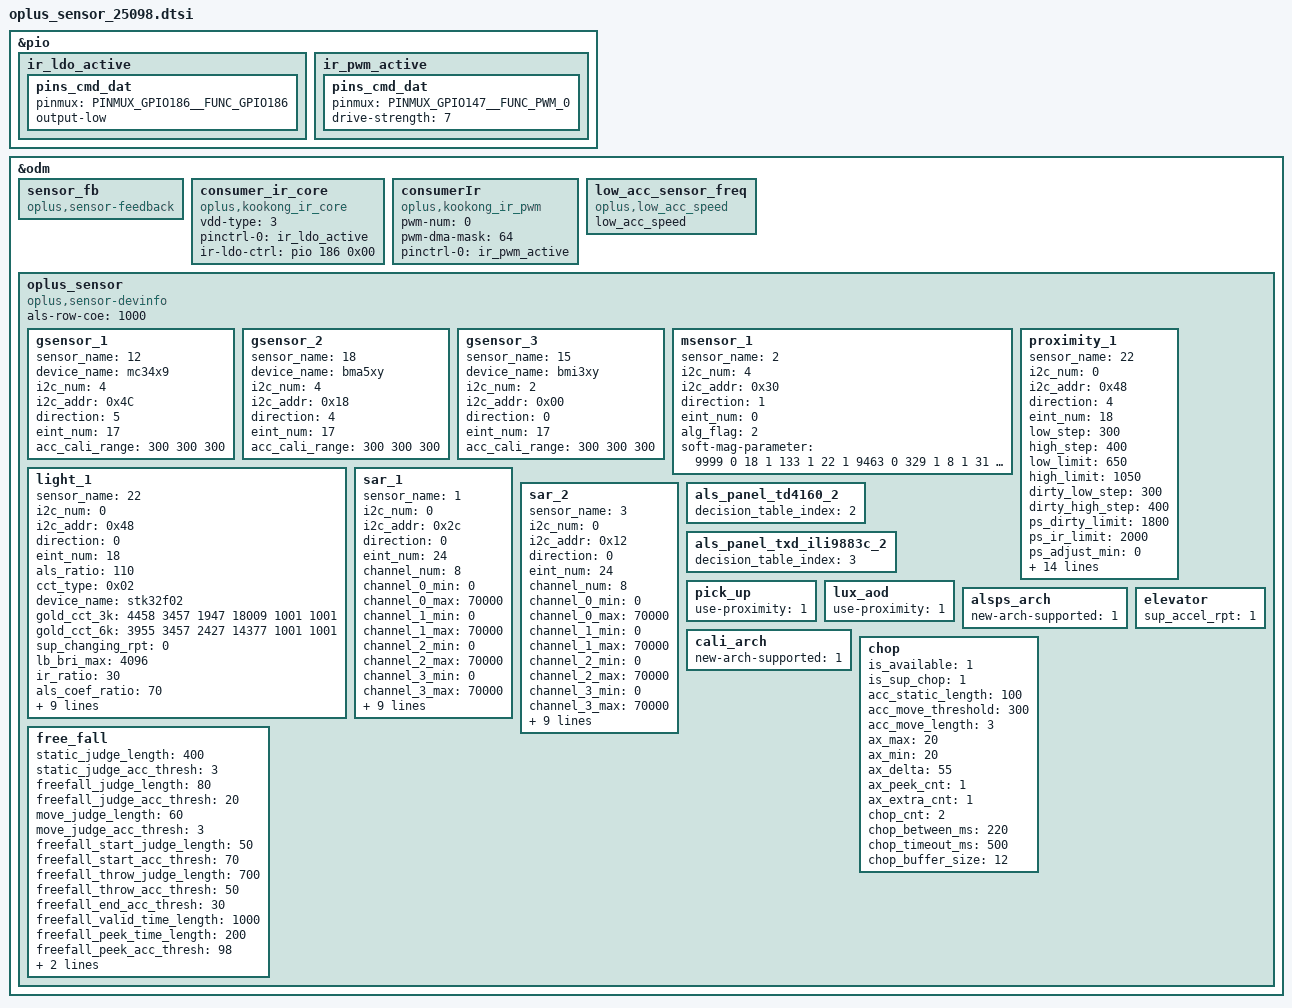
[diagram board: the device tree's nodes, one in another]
&pio {
	ir_ldo_active: ir_ldo_active {
		pins_cmd_dat {
		pinmux = <PINMUX_GPIO186__FUNC_GPIO186>;
		output-low;
		};
	};
	ir_pwm_active: ir_pwm_active{
		pins_cmd_dat {
			pinmux = <PINMUX_GPIO147__FUNC_PWM_0>;
			drive-strength = <7>;
		};
	};
};
&odm {
	sensor_fb: sensor_fb {
		compatible = "oplus,sensor-feedback";
	};
	consumer_ir_core: consumer_ir_core {
		compatible = "oplus,kookong_ir_core";
		status = "okay";
		//vdd-supply = <&mt6373_vmch_eint_high>;
		vdd-type = <3>;  /*0: internal LDO , 1: external LDO , 2: NO VDD  , 3:  GPIO VDD */
		pinctrl-names = "default";
		pinctrl-0 = <&ir_ldo_active>;
		ir-ldo-ctrl = <&pio 186 0x00>;
	};
	consumerIr: consumerIr {
		compatible = "oplus,kookong_ir_pwm";
		status = "okay";
		pwm-num = <0>;
		pwm-dma-mask = <64>;
		pinctrl-names = "default";
		pinctrl-0 = <&ir_pwm_active>;
	};
	/* Add for low acc sensor freq */
	low_acc_sensor_freq {
		compatible = "oplus,low_acc_speed";
		low_acc_speed;
	};
	oplus_sensor:oplus_sensor {
		compatible = "oplus,sensor-devinfo";
		als-row-coe = <1000>;
		/* sensor start */
		/*
		enum {
			LIS3DH,
			LSM6DS3,
			BMI160,
			LIS2HH12,
			LSM6DSM,
			BMI2XY,
			LSM6DSO,
			ICM4X6XX,
			ICM4263X,
			ICM4N607,
			BMI22X,
			SC7A20,
			MC34X9,
			BMA4XY,
			STK8329,
			BMI3XY,
			ICM456XY,
			SC7I22,
			BMA5XY,
		};
		*/
		gsensor_1: gsensor_1 {
			status = "okay";
			sensor_name = <12>;//MC34X9
			device_name = "mc34x9";
			i2c_num = <4>;
			i2c_addr = <0x4C>;
			direction = <5>;
			eint_num = <17>;
			acc_cali_range= <300 300 300>;
		};
		gsensor_2: gsensor_2 {
			status = "okay";
			sensor_name = <18>;//BMA5XY
			device_name = "bma5xy";
			i2c_num = <4>;
			i2c_addr = <0x18>;
			direction = <4>;
			eint_num = <17>;
			acc_cali_range= <300 300 300>;
		};
		gsensor_3: gsensor_3 {
			status = "okay";
			sensor_name = <15>;//BMI3XY
			device_name = "bmi3xy";
			i2c_num = <2>;
			i2c_addr = <0x00>;
			direction = <0>;
			eint_num = <17>;
			acc_cali_range= <300 300 300>;
		};
		/*
		enum {
			AKM09911,
			MMC3530,
			MMC5603,
			MXG4300,
			AKM09918,
		};
		*/
		msensor_1: msensor_1 {
			status = "okay";
			sensor_name = <2>;//MMC5603
			i2c_num = <4>;
			i2c_addr = <0x30>;
			direction = <1>;
			eint_num = <0>;
			alg_flag = <2>;
			soft-mag-parameter = <9999 0 18 1 133 1 22 1 9463 0 329 1 8 1 31 1 10402 0>;
		};
		/*
		enum {
			TMD2725,
			APSD9922,
			STK3335,
			STK3331,
			STK2232,
			TCS3701,
			STK32600,
			STK33502,
			MN78911,
			TCS3720,
			SIP3515,
			STK3329,
			LTR569,
			SIP3510,
			SIP3625,
			STK33C01,
			SIP3535,
			STK63701,
			TMD2765,
			SIP3511,
		};
		*/
		proximity_1: proximity_1 {
			status = "okay";
			sensor_name = <22>; //stk32f02
			i2c_num = <0>;
			i2c_addr = <0x48>;
			direction = <4>;
			eint_num = <18>;
			low_step = <300>;
			high_step = <400>;
			low_limit = <650>;
			high_limit = <1050>;
			dirty_low_step = <300>;
			dirty_high_step = <400>;
			ps_dirty_limit = <1800>;
			ps_ir_limit = <2000>;
			ps_adjust_min = <0>;
			ps_adjust_max = <1850>;
			sampling_count = <5>;
			step_max = <400>;
			step_min = <100>;
			step_div = <2000>;
			anti_shake_delta = <70>;
			dynamic_cali_max = <2000>;
			raw2offset_radio = <1000>;
			offset_max = <60000>;
			offset_range_min = <0>;
			offset_range_max = <65534>;
			force_cali_limit = <2000>;
			cali_jitter_limit = <20>;
			cal_offset_margin = <3000>;
		};
		light_1: light_1 {
			status = "okay";
			sensor_name = <22>; //stk32f02
			i2c_num = <0>;
			i2c_addr = <0x48>;
 			direction = <0>;
 			eint_num = <18>;
 			als_ratio = <110>;
 			cct_type = <0x02>; //0x01 CCT_NORMAL 0x02 CCT_WISE
 			device_name = "stk32f02";
 			gold_cct_3k = <4458 3457 1947 18009 1001 1001>;
 			gold_cct_6k = <3955 3457 2427 14377 1001 1001>;
 			sup_changing_rpt = <0>;
 			lb_bri_max = <4096>;
 			ir_ratio = <30>; // *100
 			als_coef_ratio = <70>; // *100
 			als_delay = <390>;
 			decision_table_index = <1>;
 			available_sensor = <14>;
 			gold_cct_factor = <941 946 924 966 1001 1001>;
 			high_pwm_cct = <1>;
 			als_timer_ms = <100>;
 			als_buffer_length = <2>;
 			need_gain_cali = <0>;
 			atime = <25000>;
		};
		/*
		enum {
			SX933x,
 			SX937x,
 			AW9610X,
 		};
 		*/
		sar_1: sar_1 {
 			status = "okay";
 			sensor_name = <1>; // SX9379
 			i2c_num = <0>;
 			i2c_addr = <0x2c>;
 			direction = <0>;
 			eint_num = <24>;
 			channel_num = <8>;
 			channel_0_min = <0>;
 			channel_0_max = <70000>;
 			channel_1_min = <0>;
 			channel_1_max = <70000>;
 			channel_2_min = <0>;
 			channel_2_max = <70000>;
 			channel_3_min = <0>;
 			channel_3_max = <70000>;
 			channel_4_min = <0>;
 			channel_4_max = <70000>;
 			channel_5_min = <0>;
 			channel_5_max = <70000>;
 			channel_6_min = <0>;
 			channel_6_max = <70000>;
 			channel_7_min = <0>;
 			channel_7_max = <70000>;
 			reg_table_num = <7>; //DB5
 		};
		sar_2: sar_2 {
 			status = "okay";
 			sensor_name = <3>; // AW96308
 			i2c_num = <0>;
 			i2c_addr = <0x12>;
 			direction = <0>;
 			eint_num = <24>;
			channel_num = <8>;
			channel_0_min = <0>;
 			channel_0_max = <70000>;
 			channel_1_min = <0>;
 			channel_1_max = <70000>;
 			channel_2_min = <0>;
 			channel_2_max = <70000>;
 			channel_3_min = <0>;
 			channel_3_max = <70000>;
 			channel_4_min = <0>;
 			channel_4_max = <70000>;
 			channel_5_min = <0>;
 			channel_5_max = <70000>;
 			channel_6_min = <0>;
 			channel_6_max = <70000>;
 			channel_7_min = <0>;
 			channel_7_max = <70000>;
 			reg_table_num = <1>;
 		};
		als_panel_td4160_2: als_panel_td4160_2 {
			status = "okay";
			decision_table_index = <2>;
		};
		als_panel_txd_ili9883c_2: als_panel_txd_ili9883c_2 {
			status = "okay";
			decision_table_index = <3>;
		};
		pick_up: pick_up {
			status = "okay";
			use-proximity = <1>;
		};
		lux_aod: lux_aod {
			status = "okay";
			use-proximity = <1>;
		};
		alsps_arch: alsps_arch {
			status = "okay";
			new-arch-supported = <1>;
		};
		cali_arch: cali_arch {
			status = "okay";
			new-arch-supported = <1>;
		};
		chop: chop {
			status = "okay";
			is_available = <1>;
			is_sup_chop = <1>;

			acc_static_length = <100>;
			acc_move_threshold = <300>;
			acc_move_length = <3>;
			ax_max = <20>;
			ax_min = <20>;
			ax_delta = <55>;
			ax_peek_cnt = <1>;
			ax_extra_cnt = <1>;
			chop_cnt = <2>;
			chop_between_ms = <220>;
			chop_timeout_ms = <500>;
			chop_buffer_size = <12>;
		};
		elevator: elevator{
			status = "okay";
			sup_accel_rpt = <1>;
		};
		free_fall: free_fall{
			status = "okay";
			static_judge_length = <400>;
			static_judge_acc_thresh = <3>;
			freefall_judge_length = <80>;
			freefall_judge_acc_thresh = <20>;
			move_judge_length = <60>;
			move_judge_acc_thresh = <3>;
			freefall_start_judge_length  = <50>;
			freefall_start_acc_thresh = <70>;
			freefall_throw_judge_length = <700>;
			freefall_throw_acc_thresh = <50>;
			freefall_end_acc_thresh = <30>;
			freefall_valid_time_length = <1000>;
			freefall_peek_time_length = <200>;
			freefall_peek_acc_thresh = <98>;
			freefall_material_thresh = <900>;
			valid_peek_interval_thresh = <10000>;
		};
	};
/* sensor end */
};
